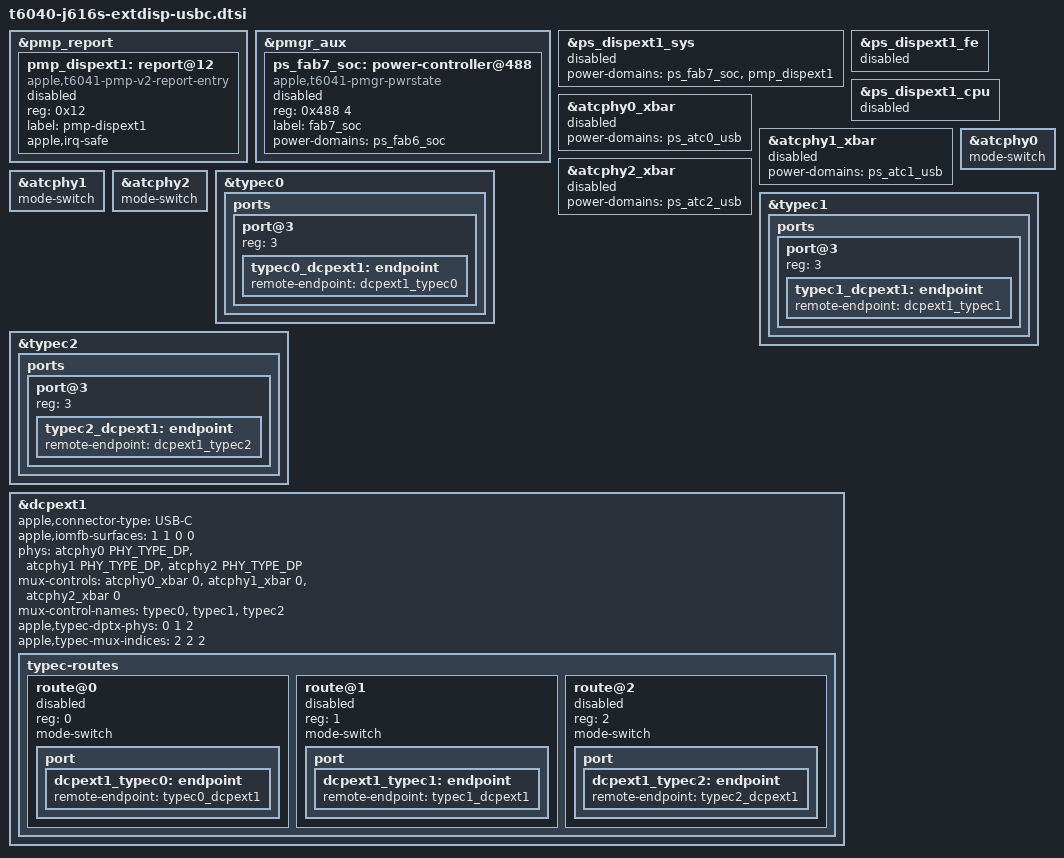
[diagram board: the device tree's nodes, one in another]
// SPDX-License-Identifier: GPL-2.0+ OR MIT
/*
 * USB-C DisplayPort through the display fabric: dcpext1 over any of the
 * three Type-C ports. As for HDMI, the DISPEXT1 chain and dcpext1 stay
 * DISABLED in the DTB. The routes (typec-routes, end of this file) are
 * disabled too and must be enabled together with dcpext1: tipd looks for
 * display routes only at probe. Boot-time changes: mode-switch on
 * atcphy0..2 (the PHY registers a Type-C mode switch; tipd drives it) and
 * the port@3 route endpoints of the connectors.
 */

/* PMP device-state acknowledgement for DISPEXT1 (soc-device 19, request bit 18), as DISPEXT0. */
&pmp_report {
	pmp_dispext1: report@12 {
		compatible = "apple,t6041-pmp-v2-report-entry",
			     "apple,t6000-pmp-v2-report-entry";
		reg = <0x12>;
		label = "pmp-dispext1";
		#power-domain-cells = <0>;
		apple,irq-safe;
		status = "disabled";
	};
};

/*
 * DISPEXT1_SYS sits on FAB7_SOC (ADT pmgr device id2 134, pmgr_aux 0x488, parent
 * FAB6_SOC, off at boot), which t6040-pmgr.dtsi does not describe. m4.62 enabled
 * DISPEXT1_SYS without it and the first DCPEXT1 register access (its DART) reset
 * the SoC. DISPEXT0_SYS's parent FAB2_SOC is on anyway through ATC0..2_COMMON.
 */
&pmgr_aux {
	ps_fab7_soc: power-controller@488 {
		compatible = "apple,t6041-pmgr-pwrstate", "apple,t8103-pmgr-pwrstate";
		reg = <0x488 4>;
		#power-domain-cells = <0>;
		#reset-cells = <0>;
		label = "fab7_soc";
		power-domains = <&ps_fab6_soc>;
		status = "disabled";
	};
};

&ps_dispext1_sys {
	power-domains = <&ps_fab7_soc>, <&pmp_dispext1>;
	status = "disabled";
};

&ps_dispext1_fe {
	status = "disabled";
};

&ps_dispext1_cpu {
	/* NEVER enable: ADT no_ps, as DISPEXT0_CPU (its register read resets the SoC). */
	/delete-property/ apple,always-on;
	status = "disabled";
};

/* The per-ATC crossbars of the Type-C ports: the ATC USB domain, as atcphy3's. */
&atcphy0_xbar {
	power-domains = <&ps_atc0_usb>;
	status = "disabled";
};

&atcphy1_xbar {
	power-domains = <&ps_atc1_usb>;
	status = "disabled";
};

&atcphy2_xbar {
	power-domains = <&ps_atc2_usb>;
	status = "disabled";
};

/* tipd switches the PHY into DP alt mode through the connector graph. */
&atcphy0 {
	mode-switch;
};

&atcphy1 {
	mode-switch;
};

&atcphy2 {
	mode-switch;
};

/*
 * Type-C display routes through the display fabric, as T6030 and J700:
 * dcpext1 offers one route per port, each a mode switch the port controller
 * drives over the connector graph (port@3). A route stays disabled until
 * the display gate enables it together with dcpext1: tipd looks for display
 * routes at probe only, and an available route without a registered mode
 * switch would make the port wait for one forever. The steps rebind tipd once
 * the routes are registered.
 */
&typec0 {
	ports {
		port@3 {
			reg = <3>;

			typec0_dcpext1: endpoint {
				remote-endpoint = <&dcpext1_typec0>;
			};
		};
	};
};

&typec1 {
	ports {
		port@3 {
			reg = <3>;

			typec1_dcpext1: endpoint {
				remote-endpoint = <&dcpext1_typec1>;
			};
		};
	};
};

&typec2 {
	ports {
		port@3 {
			reg = <3>;

			typec2_dcpext1: endpoint {
				remote-endpoint = <&dcpext1_typec2>;
			};
		};
	};
};

&dcpext1 {
	apple,connector-type = "USB-C";
	/* as dcpext0: without it apple-dcp's probe fails with -EINVAL (m4.63) */
	apple,iomfb-surfaces = <1 1 0 0>;
	phys = <&atcphy0 PHY_TYPE_DP>, <&atcphy1 PHY_TYPE_DP>, <&atcphy2 PHY_TYPE_DP>;
	phy-names = "typec0", "typec1", "typec2";
	mux-controls = <&atcphy0_xbar 0>, <&atcphy1_xbar 0>, <&atcphy2_xbar 0>;
	mux-control-names = "typec0", "typec1", "typec2";
	/* ADT: atcN-dpphy dp-switch-dfp-endpoint N; dcpext1 ufp 1 port 0 = crossbar state 2 */
	apple,typec-dptx-phys = <0 1 2>;
	apple,typec-mux-indices = <2 2 2>;

	typec-routes {
		#address-cells = <1>;
		#size-cells = <0>;

		route@0 {
			reg = <0>;
			mode-switch;
			status = "disabled";

			port {
				dcpext1_typec0: endpoint {
					remote-endpoint = <&typec0_dcpext1>;
				};
			};
		};

		route@1 {
			reg = <1>;
			mode-switch;
			status = "disabled";

			port {
				dcpext1_typec1: endpoint {
					remote-endpoint = <&typec1_dcpext1>;
				};
			};
		};

		route@2 {
			reg = <2>;
			mode-switch;
			status = "disabled";

			port {
				dcpext1_typec2: endpoint {
					remote-endpoint = <&typec2_dcpext1>;
				};
			};
		};
	};
};
